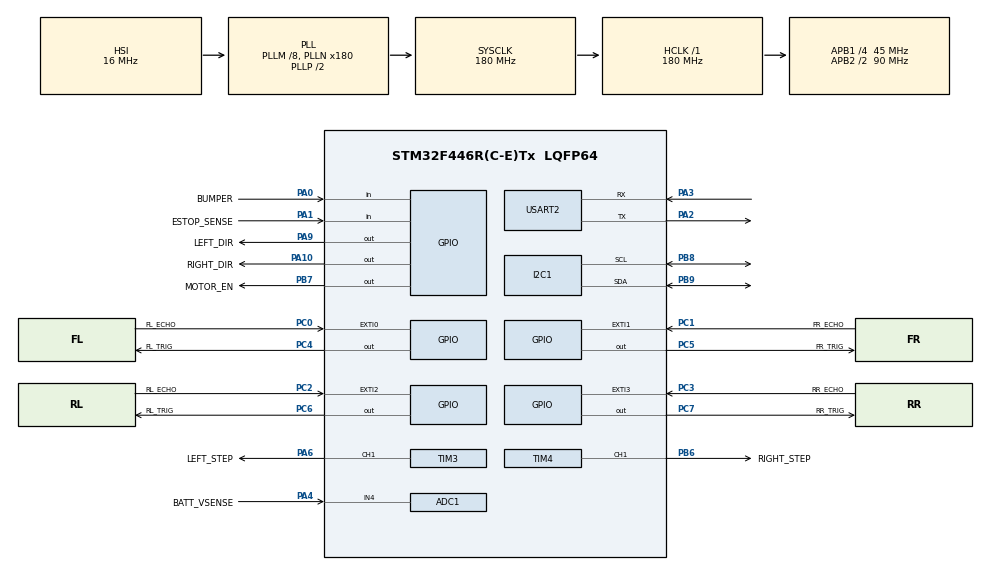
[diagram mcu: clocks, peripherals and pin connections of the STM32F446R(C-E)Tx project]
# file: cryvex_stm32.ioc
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ADC1.Channel-0\#ChannelRegularConversion=ADC_CHANNEL_4
ADC1.NbrOfConversionFlag=1
ADC1.Rank-0\#ChannelRegularConversion=1
ADC1.SamplingTime-0\#ChannelRegularConversion=ADC_SAMPLETIME_84CYCLES
ADC1.master=1
Mcu.Family=STM32F4
Mcu.Name=STM32F446R(C-E)Tx
Mcu.Package=LQFP64
NVIC.PriorityGroup=NVIC_PRIORITYGROUP_4
NVIC.USART2_IRQn=true\:0\:0\:true\:false\:true\:true\:true\:true
PA0-WKUP.GPIO_Label=BUMPER
PA0-WKUP.GPIO_PuPd=GPIO_PULLUP
PA0-WKUP.Signal=GPIO_Input
PA1.GPIO_Label=ESTOP_SENSE
PA1.GPIO_PuPd=GPIO_PULLUP
PA1.Signal=GPIO_Input
PA10.GPIO_Label=RIGHT_DIR
PA10.Signal=GPIO_Output
PA13.Mode=Serial_Wire
PA13.Signal=SYS_JTMS-SWDIO
PA14.Mode=Serial_Wire
PA14.Signal=SYS_JTCK-SWCLK
PA2.Mode=Asynchronous
PA2.Signal=USART2_TX
PA3.Mode=Asynchronous
PA3.Signal=USART2_RX
PA4.GPIO_Label=BATT_VSENSE
PA4.Signal=ADCx_IN4
PA6.GPIO_Label=LEFT_STEP
PA6.Signal=S_TIM3_CH1
PA9.GPIO_Label=LEFT_DIR
PA9.Signal=GPIO_Output
PB6.GPIO_Label=RIGHT_STEP
PB6.Signal=S_TIM4_CH1
PB7.GPIO_Label=MOTOR_EN
PB7.Signal=GPIO_Output
PB8.Mode=I2C
PB8.Signal=I2C1_SCL
PB9.Mode=I2C
PB9.Signal=I2C1_SDA
PC0.GPIO_Label=FL_ECHO
PC0.GPIO_ModeDefaultEXTI=GPIO_MODE_IT_RISING
PC0.Signal=GPXTI0
PC1.GPIO_Label=FR_ECHO
PC1.GPIO_ModeDefaultEXTI=GPIO_MODE_IT_RISING
PC1.Signal=GPXTI1
PC2.GPIO_Label=RL_ECHO
PC2.GPIO_ModeDefaultEXTI=GPIO_MODE_IT_RISING
PC2.Signal=GPXTI2
PC3.GPIO_Label=RR_ECHO
PC3.GPIO_ModeDefaultEXTI=GPIO_MODE_IT_RISING
PC3.Signal=GPXTI3
PC4.GPIO_Label=FL_TRIG
PC4.Signal=GPIO_Output
PC5.GPIO_Label=FR_TRIG
PC5.Signal=GPIO_Output
PC6.GPIO_Label=RL_TRIG
PC6.Signal=GPIO_Output
PC7.GPIO_Label=RR_TRIG
PC7.Signal=GPIO_Output
ProjectManager.HeapSize=0x200
ProjectManager.StackSize=0x400
ProjectManager.TargetToolchain=STM32CubeIDE
RCC.AHBFreq_Value=180000000
RCC.APB1CLKDivider=RCC_HCLK_DIV4
RCC.APB1Freq_Value=45000000
RCC.APB1TimFreq_Value=90000000
RCC.APB2CLKDivider=RCC_HCLK_DIV2
RCC.APB2Freq_Value=90000000
RCC.APB2TimFreq_Value=180000000
RCC.CortexFreq_Value=180000000
RCC.HCLKFreq_Value=180000000
RCC.HSE_VALUE=8000000
RCC.HSI_VALUE=16000000
RCC.PLLM=8
RCC.PLLN=180
RCC.PLLQ=4
RCC.PLLSourceVirtual=RCC_PLLSOURCE_HSI
RCC.SYSCLKFreq_VALUE=180000000
RCC.SYSCLKSource=RCC_SYSCLKSOURCE_PLLCLK
RCC.USBFreq_Value=90000000
RCC.VCOOutputFreq_Value=360000000
SH.ADCx_IN4.0=ADC1_IN4,IN4
SH.S_TIM3_CH1.0=TIM3_CH1,PWM Generation1 CH1
SH.S_TIM4_CH1.0=TIM4_CH1,PWM Generation1 CH1
TIM2.Period=4294967295
TIM2.Prescaler=89
TIM3.AutoReloadPreload=TIM_AUTORELOAD_PRELOAD_ENABLE
TIM3.Channel-PWM\ Generation1\ CH1=TIM_CHANNEL_1
TIM3.Period=999
TIM3.Prescaler=89
TIM4.AutoReloadPreload=TIM_AUTORELOAD_PRELOAD_ENABLE
TIM4.Channel-PWM\ Generation1\ CH1=TIM_CHANNEL_1
TIM4.Period=999
TIM4.Prescaler=89
USART2.VirtualMode=VM_ASYNC
VP_TIM2_VS_ClockSourceINT.Mode=Internal
board=NUCLEO-F446RE

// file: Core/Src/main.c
/* USER CODE BEGIN Header */
/**
  ******************************************************************************
  * @file           : main.c
  * @brief          : Main program body
  ******************************************************************************
  * @attention
  *
  * Copyright (c) 2026 STMicroelectronics.
  * All rights reserved.
  *
  * This software is licensed under terms that can be found in the LICENSE file
  * in the root directory of this software component.
  * If no LICENSE file comes with this software, it is provided AS-IS.
  *
  ******************************************************************************
  */
/* USER CODE END Header */
#include "main.h"

/* USER CODE BEGIN Includes */
#include "app_main.h"
#include "protocol.h"
#include "sonar.h"
/* USER CODE END Includes */

ADC_HandleTypeDef hadc1;

I2C_HandleTypeDef hi2c1;

TIM_HandleTypeDef htim2;
TIM_HandleTypeDef htim3;
TIM_HandleTypeDef htim4;

UART_HandleTypeDef huart2;

void SystemClock_Config(void);
static void MX_GPIO_Init(void);
static void MX_USART2_UART_Init(void);
static void MX_I2C1_Init(void);
static void MX_TIM2_Init(void);
static void MX_ADC1_Init(void);
static void MX_TIM3_Init(void);
static void MX_TIM4_Init(void);

int main(void)
{

  /* MCU Configuration--------------------------------------------------------*/

  /* Reset of all peripherals, Initializes the Flash interface and the Systick. */
  HAL_Init();

  /* Configure the system clock */
  SystemClock_Config();

  /* Initialize all configured peripherals */
  MX_GPIO_Init();
  MX_USART2_UART_Init();
  MX_I2C1_Init();
  MX_TIM2_Init();
  MX_ADC1_Init();
  MX_TIM3_Init();
  MX_TIM4_Init();
  /* USER CODE BEGIN 2 */
  app_init(&huart2, &htim3, &htim4, &hadc1, &hi2c1, &htim2);
  /* USER CODE END 2 */

  /* Infinite loop */
  while (1)
  {

    /* USER CODE BEGIN 3 */
    app_loop();
  }
  /* USER CODE END 3 */
}

void SystemClock_Config(void)
{
  RCC_OscInitTypeDef RCC_OscInitStruct = {0};
  RCC_ClkInitTypeDef RCC_ClkInitStruct = {0};

  /** Configure the main internal regulator output voltage
  */
  __HAL_RCC_PWR_CLK_ENABLE();
  __HAL_PWR_VOLTAGESCALING_CONFIG(PWR_REGULATOR_VOLTAGE_SCALE1);

  /** Initializes the RCC Oscillators according to the specified parameters
  * in the RCC_OscInitTypeDef structure.
  */
  RCC_OscInitStruct.OscillatorType = RCC_OSCILLATORTYPE_HSI;
  RCC_OscInitStruct.HSIState = RCC_HSI_ON;
  RCC_OscInitStruct.HSICalibrationValue = RCC_HSICALIBRATION_DEFAULT;
  RCC_OscInitStruct.PLL.PLLState = RCC_PLL_ON;
  RCC_OscInitStruct.PLL.PLLSource = RCC_PLLSOURCE_HSI;
  RCC_OscInitStruct.PLL.PLLM = 8;
  RCC_OscInitStruct.PLL.PLLN = 180;
  RCC_OscInitStruct.PLL.PLLP = RCC_PLLP_DIV2;
  RCC_OscInitStruct.PLL.PLLQ = 4;
  RCC_OscInitStruct.PLL.PLLR = 2;
  if (HAL_RCC_OscConfig(&RCC_OscInitStruct) != HAL_OK)
  {
    Error_Handler();
  }

  /** Activate the Over-Drive mode
  */
  if (HAL_PWREx_EnableOverDrive() != HAL_OK)
  {
    Error_Handler();
  }

  /** Initializes the CPU, AHB and APB buses clocks
  */
  RCC_ClkInitStruct.ClockType = RCC_CLOCKTYPE_HCLK|RCC_CLOCKTYPE_SYSCLK
                              |RCC_CLOCKTYPE_PCLK1|RCC_CLOCKTYPE_PCLK2;
  RCC_ClkInitStruct.SYSCLKSource = RCC_SYSCLKSOURCE_PLLCLK;
  RCC_ClkInitStruct.AHBCLKDivider = RCC_SYSCLK_DIV1;
  RCC_ClkInitStruct.APB1CLKDivider = RCC_HCLK_DIV4;
  RCC_ClkInitStruct.APB2CLKDivider = RCC_HCLK_DIV2;

  if (HAL_RCC_ClockConfig(&RCC_ClkInitStruct, FLASH_LATENCY_5) != HAL_OK)
  {
    Error_Handler();
  }
}

static void MX_ADC1_Init(void)
{

  ADC_ChannelConfTypeDef sConfig = {0};

  /** Configure the global features of the ADC (Clock, Resolution, Data Alignment and number of conversion)
  */
  hadc1.Instance = ADC1;
  hadc1.Init.ClockPrescaler = ADC_CLOCK_SYNC_PCLK_DIV4;
  hadc1.Init.Resolution = ADC_RESOLUTION_12B;
  hadc1.Init.ScanConvMode = DISABLE;
  hadc1.Init.ContinuousConvMode = DISABLE;
  hadc1.Init.DiscontinuousConvMode = DISABLE;
  hadc1.Init.ExternalTrigConvEdge = ADC_EXTERNALTRIGCONVEDGE_NONE;
  hadc1.Init.ExternalTrigConv = ADC_SOFTWARE_START;
  hadc1.Init.DataAlign = ADC_DATAALIGN_RIGHT;
  hadc1.Init.NbrOfConversion = 1;
  hadc1.Init.DMAContinuousRequests = DISABLE;
  hadc1.Init.EOCSelection = ADC_EOC_SINGLE_CONV;
  if (HAL_ADC_Init(&hadc1) != HAL_OK)
  {
    Error_Handler();
  }

  /** Configure for the selected ADC regular channel its corresponding rank in the sequencer and its sample time.
  */
  sConfig.Channel = ADC_CHANNEL_4;
  sConfig.Rank = 1;
  sConfig.SamplingTime = ADC_SAMPLETIME_84CYCLES;
  if (HAL_ADC_ConfigChannel(&hadc1, &sConfig) != HAL_OK)
  {
    Error_Handler();
  }

}

static void MX_I2C1_Init(void)
{

  hi2c1.Instance = I2C1;
  hi2c1.Init.ClockSpeed = 100000;
  hi2c1.Init.DutyCycle = I2C_DUTYCYCLE_2;
  hi2c1.Init.OwnAddress1 = 0;
  hi2c1.Init.AddressingMode = I2C_ADDRESSINGMODE_7BIT;
  hi2c1.Init.DualAddressMode = I2C_DUALADDRESS_DISABLE;
  hi2c1.Init.OwnAddress2 = 0;
  hi2c1.Init.GeneralCallMode = I2C_GENERALCALL_DISABLE;
  hi2c1.Init.NoStretchMode = I2C_NOSTRETCH_DISABLE;
  if (HAL_I2C_Init(&hi2c1) != HAL_OK)
  {
    Error_Handler();
  }

}

static void MX_TIM2_Init(void)
{

  TIM_ClockConfigTypeDef sClockSourceConfig = {0};
  TIM_MasterConfigTypeDef sMasterConfig = {0};

  htim2.Instance = TIM2;
  htim2.Init.Prescaler = 89;
  htim2.Init.CounterMode = TIM_COUNTERMODE_UP;
  htim2.Init.Period = 4294967295;
  htim2.Init.ClockDivision = TIM_CLOCKDIVISION_DIV1;
  htim2.Init.AutoReloadPreload = TIM_AUTORELOAD_PRELOAD_DISABLE;
  if (HAL_TIM_Base_Init(&htim2) != HAL_OK)
  {
    Error_Handler();
  }
  sClockSourceConfig.ClockSource = TIM_CLOCKSOURCE_INTERNAL;
  if (HAL_TIM_ConfigClockSource(&htim2, &sClockSourceConfig) != HAL_OK)
  {
    Error_Handler();
  }
  sMasterConfig.MasterOutputTrigger = TIM_TRGO_RESET;
  sMasterConfig.MasterSlaveMode = TIM_MASTERSLAVEMODE_DISABLE;
  if (HAL_TIMEx_MasterConfigSynchronization(&htim2, &sMasterConfig) != HAL_OK)
  {
    Error_Handler();
  }

}

static void MX_TIM3_Init(void)
{

  TIM_MasterConfigTypeDef sMasterConfig = {0};
  TIM_OC_InitTypeDef sConfigOC = {0};

  htim3.Instance = TIM3;
  htim3.Init.Prescaler = 89;
  htim3.Init.CounterMode = TIM_COUNTERMODE_UP;
  htim3.Init.Period = 999;
  htim3.Init.ClockDivision = TIM_CLOCKDIVISION_DIV1;
  htim3.Init.AutoReloadPreload = TIM_AUTORELOAD_PRELOAD_ENABLE;
  if (HAL_TIM_PWM_Init(&htim3) != HAL_OK)
  {
    Error_Handler();
  }
  sMasterConfig.MasterOutputTrigger = TIM_TRGO_RESET;
  sMasterConfig.MasterSlaveMode = TIM_MASTERSLAVEMODE_DISABLE;
  if (HAL_TIMEx_MasterConfigSynchronization(&htim3, &sMasterConfig) != HAL_OK)
  {
    Error_Handler();
  }
  sConfigOC.OCMode = TIM_OCMODE_PWM1;
  sConfigOC.Pulse = 0;
  sConfigOC.OCPolarity = TIM_OCPOLARITY_HIGH;
  sConfigOC.OCFastMode = TIM_OCFAST_DISABLE;
  if (HAL_TIM_PWM_ConfigChannel(&htim3, &sConfigOC, TIM_CHANNEL_1) != HAL_OK)
  {
    Error_Handler();
  }
  HAL_TIM_MspPostInit(&htim3);

}

static void MX_TIM4_Init(void)
{

  TIM_MasterConfigTypeDef sMasterConfig = {0};
  TIM_OC_InitTypeDef sConfigOC = {0};

  htim4.Instance = TIM4;
  htim4.Init.Prescaler = 89;
  htim4.Init.CounterMode = TIM_COUNTERMODE_UP;
  htim4.Init.Period = 999;
  htim4.Init.ClockDivision = TIM_CLOCKDIVISION_DIV1;
  htim4.Init.AutoReloadPreload = TIM_AUTORELOAD_PRELOAD_ENABLE;
  if (HAL_TIM_PWM_Init(&htim4) != HAL_OK)
  {
    Error_Handler();
  }
  sMasterConfig.MasterOutputTrigger = TIM_TRGO_RESET;
  sMasterConfig.MasterSlaveMode = TIM_MASTERSLAVEMODE_DISABLE;
  if (HAL_TIMEx_MasterConfigSynchronization(&htim4, &sMasterConfig) != HAL_OK)
  {
    Error_Handler();
  }
  sConfigOC.OCMode = TIM_OCMODE_PWM1;
  sConfigOC.Pulse = 0;
  sConfigOC.OCPolarity = TIM_OCPOLARITY_HIGH;
  sConfigOC.OCFastMode = TIM_OCFAST_DISABLE;
  if (HAL_TIM_PWM_ConfigChannel(&htim4, &sConfigOC, TIM_CHANNEL_1) != HAL_OK)
  {
    Error_Handler();
  }
  HAL_TIM_MspPostInit(&htim4);

}

static void MX_USART2_UART_Init(void)
{

  huart2.Instance = USART2;
  huart2.Init.BaudRate = 115200;
  huart2.Init.WordLength = UART_WORDLENGTH_8B;
  huart2.Init.StopBits = UART_STOPBITS_1;
  huart2.Init.Parity = UART_PARITY_NONE;
  huart2.Init.Mode = UART_MODE_TX_RX;
  huart2.Init.HwFlowCtl = UART_HWCONTROL_NONE;
  huart2.Init.OverSampling = UART_OVERSAMPLING_16;
  if (HAL_UART_Init(&huart2) != HAL_OK)
  {
    Error_Handler();
  }

}

static void MX_GPIO_Init(void)
{
  GPIO_InitTypeDef GPIO_InitStruct = {0};

  /* GPIO Ports Clock Enable */
  __HAL_RCC_GPIOC_CLK_ENABLE();
  __HAL_RCC_GPIOA_CLK_ENABLE();
  __HAL_RCC_GPIOB_CLK_ENABLE();

  /*Configure GPIO pin Output Level */
  HAL_GPIO_WritePin(GPIOC, FL_TRIG_Pin|FR_TRIG_Pin|RL_TRIG_Pin|RR_TRIG_Pin, GPIO_PIN_RESET);

  /*Configure GPIO pin Output Level */
  HAL_GPIO_WritePin(GPIOA, LEFT_DIR_Pin|RIGHT_DIR_Pin, GPIO_PIN_RESET);

  /*Configure GPIO pin Output Level */
  HAL_GPIO_WritePin(MOTOR_EN_GPIO_Port, MOTOR_EN_Pin, GPIO_PIN_RESET);

  /*Configure GPIO pins : FL_ECHO_Pin FR_ECHO_Pin RL_ECHO_Pin RR_ECHO_Pin */
  GPIO_InitStruct.Pin = FL_ECHO_Pin|FR_ECHO_Pin|RL_ECHO_Pin|RR_ECHO_Pin;
  GPIO_InitStruct.Mode = GPIO_MODE_IT_RISING;
  GPIO_InitStruct.Pull = GPIO_NOPULL;
  HAL_GPIO_Init(GPIOC, &GPIO_InitStruct);

  /*Configure GPIO pins : BUMPER_Pin ESTOP_SENSE_Pin */
  GPIO_InitStruct.Pin = BUMPER_Pin|ESTOP_SENSE_Pin;
  GPIO_InitStruct.Mode = GPIO_MODE_INPUT;
  GPIO_InitStruct.Pull = GPIO_PULLUP;
  HAL_GPIO_Init(GPIOA, &GPIO_InitStruct);

  /*Configure GPIO pins : FL_TRIG_Pin FR_TRIG_Pin RL_TRIG_Pin RR_TRIG_Pin */
  GPIO_InitStruct.Pin = FL_TRIG_Pin|FR_TRIG_Pin|RL_TRIG_Pin|RR_TRIG_Pin;
  GPIO_InitStruct.Mode = GPIO_MODE_OUTPUT_PP;
  GPIO_InitStruct.Pull = GPIO_NOPULL;
  GPIO_InitStruct.Speed = GPIO_SPEED_FREQ_LOW;
  HAL_GPIO_Init(GPIOC, &GPIO_InitStruct);

  /*Configure GPIO pins : LEFT_DIR_Pin RIGHT_DIR_Pin */
  GPIO_InitStruct.Pin = LEFT_DIR_Pin|RIGHT_DIR_Pin;
  GPIO_InitStruct.Mode = GPIO_MODE_OUTPUT_PP;
  GPIO_InitStruct.Pull = GPIO_NOPULL;
  GPIO_InitStruct.Speed = GPIO_SPEED_FREQ_LOW;
  HAL_GPIO_Init(GPIOA, &GPIO_InitStruct);

  /*Configure GPIO pin : MOTOR_EN_Pin */
  GPIO_InitStruct.Pin = MOTOR_EN_Pin;
  GPIO_InitStruct.Mode = GPIO_MODE_OUTPUT_PP;
  GPIO_InitStruct.Pull = GPIO_NOPULL;
  GPIO_InitStruct.Speed = GPIO_SPEED_FREQ_LOW;
  HAL_GPIO_Init(MOTOR_EN_GPIO_Port, &GPIO_InitStruct);

}

/* USER CODE BEGIN 4 */
void HAL_UART_RxCpltCallback(UART_HandleTypeDef *huart)
{
    protocol_uart_rx_isr(huart);
}

void HAL_GPIO_EXTI_Callback(uint16_t GPIO_Pin)
{
    sonar_exti_isr(GPIO_Pin);
}
/* USER CODE END 4 */

void Error_Handler(void)
{
  __disable_irq();
  while (1)
  {
  }
}
